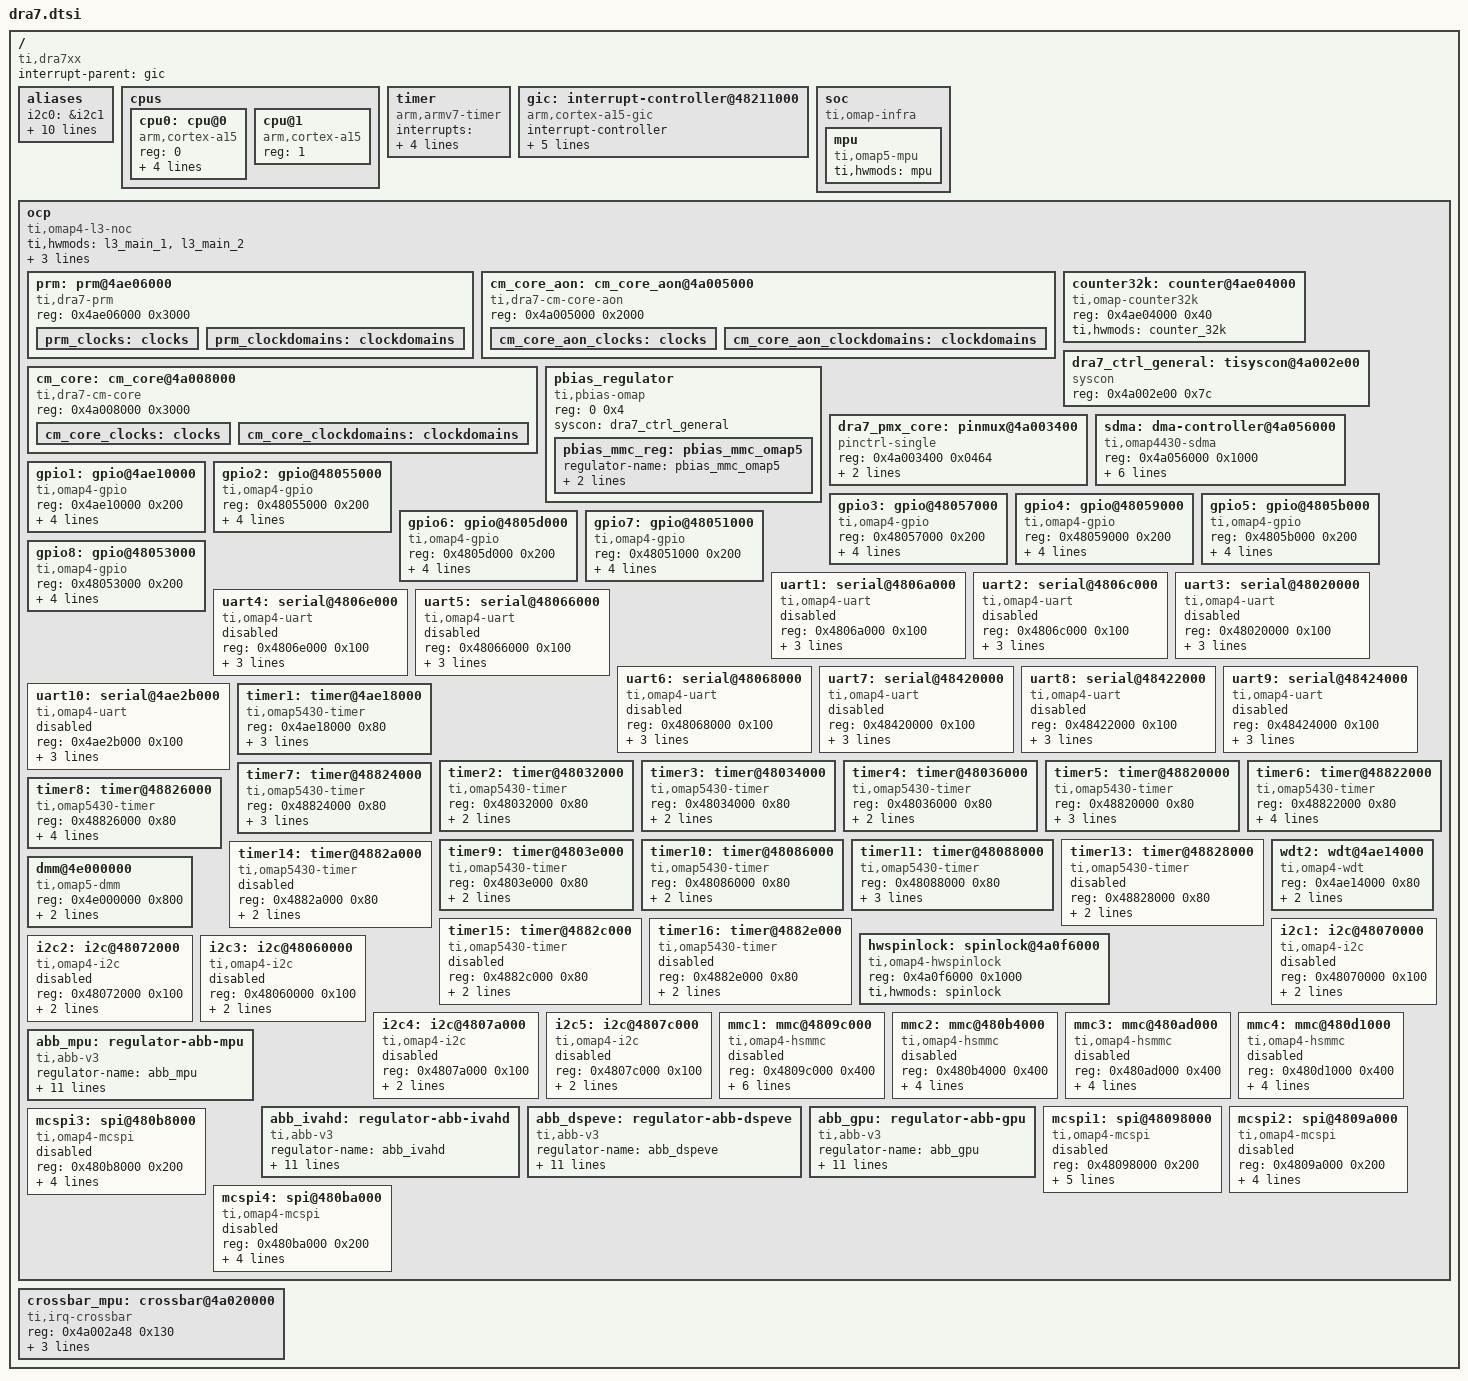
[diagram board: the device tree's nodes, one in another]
/*
 * Copyright (C) 2013 Texas Instruments Incorporated - http://www.ti.com/
 *
 * This program is free software; you can redistribute it and/or modify
 * it under the terms of the GNU General Public License version 2 as
 * published by the Free Software Foundation.
 * Based on "omap4.dtsi"
 */

#include <dt-bindings/interrupt-controller/arm-gic.h>
#include <dt-bindings/pinctrl/dra.h>

#include "skeleton.dtsi"

/ {
	#address-cells = <1>;
	#size-cells = <1>;

	compatible = "ti,dra7xx";
	interrupt-parent = <&gic>;

	aliases {
		i2c0 = &i2c1;
		i2c1 = &i2c2;
		i2c2 = &i2c3;
		i2c3 = &i2c4;
		i2c4 = &i2c5;
		serial0 = &uart1;
		serial1 = &uart2;
		serial2 = &uart3;
		serial3 = &uart4;
		serial4 = &uart5;
		serial5 = &uart6;
	};

	cpus {
		#address-cells = <1>;
		#size-cells = <0>;

		cpu0: cpu@0 {
			device_type = "cpu";
			compatible = "arm,cortex-a15";
			reg = <0>;

			operating-points = <
				/* kHz    uV */
				1000000	1060000
				1176000	1160000
				>;

			clocks = <&dpll_mpu_ck>;
			clock-names = "cpu";

			clock-latency = <300000>; /* From omap-cpufreq driver */
		};
		cpu@1 {
			device_type = "cpu";
			compatible = "arm,cortex-a15";
			reg = <1>;
		};
	};

	timer {
		compatible = "arm,armv7-timer";
		interrupts = <GIC_PPI 13 (GIC_CPU_MASK_SIMPLE(2) | IRQ_TYPE_LEVEL_LOW)>,
			     <GIC_PPI 14 (GIC_CPU_MASK_SIMPLE(2) | IRQ_TYPE_LEVEL_LOW)>,
			     <GIC_PPI 11 (GIC_CPU_MASK_SIMPLE(2) | IRQ_TYPE_LEVEL_LOW)>,
			     <GIC_PPI 10 (GIC_CPU_MASK_SIMPLE(2) | IRQ_TYPE_LEVEL_LOW)>;
	};

	gic: interrupt-controller@48211000 {
		compatible = "arm,cortex-a15-gic";
		interrupt-controller;
		#interrupt-cells = <3>;
		arm,routable-irqs = <192>;
		reg = <0x48211000 0x1000>,
		      <0x48212000 0x1000>,
		      <0x48214000 0x2000>,
		      <0x48216000 0x2000>;
		interrupts = <GIC_PPI 9 (GIC_CPU_MASK_SIMPLE(2) | IRQ_TYPE_LEVEL_HIGH)>;
	};

	/*
	 * The soc node represents the soc top level view. It is used for IPs
	 * that are not memory mapped in the MPU view or for the MPU itself.
	 */
	soc {
		compatible = "ti,omap-infra";
		mpu {
			compatible = "ti,omap5-mpu";
			ti,hwmods = "mpu";
		};
	};

	/*
	 * XXX: Use a flat representation of the SOC interconnect.
	 * The real OMAP interconnect network is quite complex.
	 * Since it will not bring real advantage to represent that in DT for
	 * the moment, just use a fake OCP bus entry to represent the whole bus
	 * hierarchy.
	 */
	ocp {
		compatible = "ti,omap4-l3-noc", "simple-bus";
		#address-cells = <1>;
		#size-cells = <1>;
		ranges;
		ti,hwmods = "l3_main_1", "l3_main_2";
		reg = <0x44000000 0x2000>,
		      <0x44800000 0x3000>;
		interrupts = <GIC_SPI 164 IRQ_TYPE_LEVEL_HIGH>,
			     <GIC_SPI 10 IRQ_TYPE_LEVEL_HIGH>;

		prm: prm@4ae06000 {
			compatible = "ti,dra7-prm";
			reg = <0x4ae06000 0x3000>;

			prm_clocks: clocks {
				#address-cells = <1>;
				#size-cells = <0>;
			};

			prm_clockdomains: clockdomains {
			};
		};

		cm_core_aon: cm_core_aon@4a005000 {
			compatible = "ti,dra7-cm-core-aon";
			reg = <0x4a005000 0x2000>;

			cm_core_aon_clocks: clocks {
				#address-cells = <1>;
				#size-cells = <0>;
			};

			cm_core_aon_clockdomains: clockdomains {
			};
		};

		cm_core: cm_core@4a008000 {
			compatible = "ti,dra7-cm-core";
			reg = <0x4a008000 0x3000>;

			cm_core_clocks: clocks {
				#address-cells = <1>;
				#size-cells = <0>;
			};

			cm_core_clockdomains: clockdomains {
			};
		};

		counter32k: counter@4ae04000 {
			compatible = "ti,omap-counter32k";
			reg = <0x4ae04000 0x40>;
			ti,hwmods = "counter_32k";
		};

		dra7_ctrl_general: tisyscon@4a002e00 {
			compatible = "syscon";
			reg = <0x4a002e00 0x7c>;
		};

		pbias_regulator: pbias_regulator {
			compatible = "ti,pbias-omap";
			reg = <0 0x4>;
			syscon = <&dra7_ctrl_general>;
			pbias_mmc_reg: pbias_mmc_omap5 {
				regulator-name = "pbias_mmc_omap5";
				regulator-min-microvolt = <1800000>;
				regulator-max-microvolt = <3000000>;
			};
		};

		dra7_pmx_core: pinmux@4a003400 {
			compatible = "pinctrl-single";
			reg = <0x4a003400 0x0464>;
			#address-cells = <1>;
			#size-cells = <0>;
			pinctrl-single,register-width = <32>;
			pinctrl-single,function-mask = <0x3fffffff>;
		};

		sdma: dma-controller@4a056000 {
			compatible = "ti,omap4430-sdma";
			reg = <0x4a056000 0x1000>;
			interrupts = <GIC_SPI 167 IRQ_TYPE_LEVEL_HIGH>,
				     <GIC_SPI 168 IRQ_TYPE_LEVEL_HIGH>,
				     <GIC_SPI 169 IRQ_TYPE_LEVEL_HIGH>,
				     <GIC_SPI 170 IRQ_TYPE_LEVEL_HIGH>;
			#dma-cells = <1>;
			#dma-channels = <32>;
			#dma-requests = <127>;
		};

		gpio1: gpio@4ae10000 {
			compatible = "ti,omap4-gpio";
			reg = <0x4ae10000 0x200>;
			interrupts = <GIC_SPI 184 IRQ_TYPE_LEVEL_HIGH>;
			ti,hwmods = "gpio1";
			gpio-controller;
			#gpio-cells = <2>;
			interrupt-controller;
			#interrupt-cells = <1>;
		};

		gpio2: gpio@48055000 {
			compatible = "ti,omap4-gpio";
			reg = <0x48055000 0x200>;
			interrupts = <GIC_SPI 185 IRQ_TYPE_LEVEL_HIGH>;
			ti,hwmods = "gpio2";
			gpio-controller;
			#gpio-cells = <2>;
			interrupt-controller;
			#interrupt-cells = <1>;
		};

		gpio3: gpio@48057000 {
			compatible = "ti,omap4-gpio";
			reg = <0x48057000 0x200>;
			interrupts = <GIC_SPI 186 IRQ_TYPE_LEVEL_HIGH>;
			ti,hwmods = "gpio3";
			gpio-controller;
			#gpio-cells = <2>;
			interrupt-controller;
			#interrupt-cells = <1>;
		};

		gpio4: gpio@48059000 {
			compatible = "ti,omap4-gpio";
			reg = <0x48059000 0x200>;
			interrupts = <GIC_SPI 187 IRQ_TYPE_LEVEL_HIGH>;
			ti,hwmods = "gpio4";
			gpio-controller;
			#gpio-cells = <2>;
			interrupt-controller;
			#interrupt-cells = <1>;
		};

		gpio5: gpio@4805b000 {
			compatible = "ti,omap4-gpio";
			reg = <0x4805b000 0x200>;
			interrupts = <GIC_SPI 188 IRQ_TYPE_LEVEL_HIGH>;
			ti,hwmods = "gpio5";
			gpio-controller;
			#gpio-cells = <2>;
			interrupt-controller;
			#interrupt-cells = <1>;
		};

		gpio6: gpio@4805d000 {
			compatible = "ti,omap4-gpio";
			reg = <0x4805d000 0x200>;
			interrupts = <GIC_SPI 189 IRQ_TYPE_LEVEL_HIGH>;
			ti,hwmods = "gpio6";
			gpio-controller;
			#gpio-cells = <2>;
			interrupt-controller;
			#interrupt-cells = <1>;
		};

		gpio7: gpio@48051000 {
			compatible = "ti,omap4-gpio";
			reg = <0x48051000 0x200>;
			interrupts = <GIC_SPI 190 IRQ_TYPE_LEVEL_HIGH>;
			ti,hwmods = "gpio7";
			gpio-controller;
			#gpio-cells = <2>;
			interrupt-controller;
			#interrupt-cells = <1>;
		};

		gpio8: gpio@48053000 {
			compatible = "ti,omap4-gpio";
			reg = <0x48053000 0x200>;
			interrupts = <GIC_SPI 276 IRQ_TYPE_LEVEL_HIGH>;
			ti,hwmods = "gpio8";
			gpio-controller;
			#gpio-cells = <2>;
			interrupt-controller;
			#interrupt-cells = <1>;
		};

		uart1: serial@4806a000 {
			compatible = "ti,omap4-uart";
			reg = <0x4806a000 0x100>;
			interrupts = <GIC_SPI 227 IRQ_TYPE_LEVEL_HIGH>;
			ti,hwmods = "uart1";
			clock-frequency = <48000000>;
			status = "disabled";
		};

		uart2: serial@4806c000 {
			compatible = "ti,omap4-uart";
			reg = <0x4806c000 0x100>;
			interrupts = <GIC_SPI 228 IRQ_TYPE_LEVEL_HIGH>;
			ti,hwmods = "uart2";
			clock-frequency = <48000000>;
			status = "disabled";
		};

		uart3: serial@48020000 {
			compatible = "ti,omap4-uart";
			reg = <0x48020000 0x100>;
			interrupts = <GIC_SPI 229 IRQ_TYPE_LEVEL_HIGH>;
			ti,hwmods = "uart3";
			clock-frequency = <48000000>;
			status = "disabled";
		};

		uart4: serial@4806e000 {
			compatible = "ti,omap4-uart";
			reg = <0x4806e000 0x100>;
			interrupts = <GIC_SPI 225 IRQ_TYPE_LEVEL_HIGH>;
			ti,hwmods = "uart4";
			clock-frequency = <48000000>;
                        status = "disabled";
		};

		uart5: serial@48066000 {
			compatible = "ti,omap4-uart";
			reg = <0x48066000 0x100>;
			interrupts = <GIC_SPI 260 IRQ_TYPE_LEVEL_HIGH>;
			ti,hwmods = "uart5";
			clock-frequency = <48000000>;
			status = "disabled";
		};

		uart6: serial@48068000 {
			compatible = "ti,omap4-uart";
			reg = <0x48068000 0x100>;
			interrupts = <GIC_SPI 261 IRQ_TYPE_LEVEL_HIGH>;
			ti,hwmods = "uart6";
			clock-frequency = <48000000>;
			status = "disabled";
		};

		uart7: serial@48420000 {
			compatible = "ti,omap4-uart";
			reg = <0x48420000 0x100>;
			interrupts = <GIC_SPI 378 IRQ_TYPE_LEVEL_HIGH>;
			ti,hwmods = "uart7";
			clock-frequency = <48000000>;
			status = "disabled";
		};

		uart8: serial@48422000 {
			compatible = "ti,omap4-uart";
			reg = <0x48422000 0x100>;
			interrupts = <GIC_SPI 379 IRQ_TYPE_LEVEL_HIGH>;
			ti,hwmods = "uart8";
			clock-frequency = <48000000>;
			status = "disabled";
		};

		uart9: serial@48424000 {
			compatible = "ti,omap4-uart";
			reg = <0x48424000 0x100>;
			interrupts = <GIC_SPI 380 IRQ_TYPE_LEVEL_HIGH>;
			ti,hwmods = "uart9";
			clock-frequency = <48000000>;
			status = "disabled";
		};

		uart10: serial@4ae2b000 {
			compatible = "ti,omap4-uart";
			reg = <0x4ae2b000 0x100>;
			interrupts = <GIC_SPI 381 IRQ_TYPE_LEVEL_HIGH>;
			ti,hwmods = "uart10";
			clock-frequency = <48000000>;
			status = "disabled";
		};

		timer1: timer@4ae18000 {
			compatible = "ti,omap5430-timer";
			reg = <0x4ae18000 0x80>;
			interrupts = <GIC_SPI 192 IRQ_TYPE_LEVEL_HIGH>;
			ti,hwmods = "timer1";
			ti,timer-alwon;
		};

		timer2: timer@48032000 {
			compatible = "ti,omap5430-timer";
			reg = <0x48032000 0x80>;
			interrupts = <GIC_SPI 193 IRQ_TYPE_LEVEL_HIGH>;
			ti,hwmods = "timer2";
		};

		timer3: timer@48034000 {
			compatible = "ti,omap5430-timer";
			reg = <0x48034000 0x80>;
			interrupts = <GIC_SPI 194 IRQ_TYPE_LEVEL_HIGH>;
			ti,hwmods = "timer3";
		};

		timer4: timer@48036000 {
			compatible = "ti,omap5430-timer";
			reg = <0x48036000 0x80>;
			interrupts = <GIC_SPI 195 IRQ_TYPE_LEVEL_HIGH>;
			ti,hwmods = "timer4";
		};

		timer5: timer@48820000 {
			compatible = "ti,omap5430-timer";
			reg = <0x48820000 0x80>;
			interrupts = <GIC_SPI 196 IRQ_TYPE_LEVEL_HIGH>;
			ti,hwmods = "timer5";
			ti,timer-dsp;
		};

		timer6: timer@48822000 {
			compatible = "ti,omap5430-timer";
			reg = <0x48822000 0x80>;
			interrupts = <GIC_SPI 197 IRQ_TYPE_LEVEL_HIGH>;
			ti,hwmods = "timer6";
			ti,timer-dsp;
			ti,timer-pwm;
		};

		timer7: timer@48824000 {
			compatible = "ti,omap5430-timer";
			reg = <0x48824000 0x80>;
			interrupts = <GIC_SPI 198 IRQ_TYPE_LEVEL_HIGH>;
			ti,hwmods = "timer7";
			ti,timer-dsp;
		};

		timer8: timer@48826000 {
			compatible = "ti,omap5430-timer";
			reg = <0x48826000 0x80>;
			interrupts = <GIC_SPI 199 IRQ_TYPE_LEVEL_HIGH>;
			ti,hwmods = "timer8";
			ti,timer-dsp;
			ti,timer-pwm;
		};

		timer9: timer@4803e000 {
			compatible = "ti,omap5430-timer";
			reg = <0x4803e000 0x80>;
			interrupts = <GIC_SPI 200 IRQ_TYPE_LEVEL_HIGH>;
			ti,hwmods = "timer9";
		};

		timer10: timer@48086000 {
			compatible = "ti,omap5430-timer";
			reg = <0x48086000 0x80>;
			interrupts = <GIC_SPI 201 IRQ_TYPE_LEVEL_HIGH>;
			ti,hwmods = "timer10";
		};

		timer11: timer@48088000 {
			compatible = "ti,omap5430-timer";
			reg = <0x48088000 0x80>;
			interrupts = <GIC_SPI 202 IRQ_TYPE_LEVEL_HIGH>;
			ti,hwmods = "timer11";
			ti,timer-pwm;
		};

		timer13: timer@48828000 {
			compatible = "ti,omap5430-timer";
			reg = <0x48828000 0x80>;
			interrupts = <GIC_SPI 499 IRQ_TYPE_LEVEL_HIGH>;
			ti,hwmods = "timer13";
			status = "disabled";
		};

		timer14: timer@4882a000 {
			compatible = "ti,omap5430-timer";
			reg = <0x4882a000 0x80>;
			interrupts = <GIC_SPI 500 IRQ_TYPE_LEVEL_HIGH>;
			ti,hwmods = "timer14";
			status = "disabled";
		};

		timer15: timer@4882c000 {
			compatible = "ti,omap5430-timer";
			reg = <0x4882c000 0x80>;
			interrupts = <GIC_SPI 501 IRQ_TYPE_LEVEL_HIGH>;
			ti,hwmods = "timer15";
			status = "disabled";
		};

		timer16: timer@4882e000 {
			compatible = "ti,omap5430-timer";
			reg = <0x4882e000 0x80>;
			interrupts = <GIC_SPI 502 IRQ_TYPE_LEVEL_HIGH>;
			ti,hwmods = "timer16";
			status = "disabled";
		};

		wdt2: wdt@4ae14000 {
			compatible = "ti,omap4-wdt";
			reg = <0x4ae14000 0x80>;
			interrupts = <GIC_SPI 235 IRQ_TYPE_LEVEL_HIGH>;
			ti,hwmods = "wd_timer2";
		};

		hwspinlock: spinlock@4a0f6000 {
			compatible = "ti,omap4-hwspinlock";
			reg = <0x4a0f6000 0x1000>;
			ti,hwmods = "spinlock";
			#hwlock-cells = <1>;
		};

		dmm@4e000000 {
			compatible = "ti,omap5-dmm";
			reg = <0x4e000000 0x800>;
			interrupts = <GIC_SPI 268 IRQ_TYPE_LEVEL_HIGH>;
			ti,hwmods = "dmm";
		};

		i2c1: i2c@48070000 {
			compatible = "ti,omap4-i2c";
			reg = <0x48070000 0x100>;
			interrupts = <GIC_SPI 211 IRQ_TYPE_LEVEL_HIGH>;
			#address-cells = <1>;
			#size-cells = <0>;
			ti,hwmods = "i2c1";
			status = "disabled";
		};

		i2c2: i2c@48072000 {
			compatible = "ti,omap4-i2c";
			reg = <0x48072000 0x100>;
			interrupts = <GIC_SPI 212 IRQ_TYPE_LEVEL_HIGH>;
			#address-cells = <1>;
			#size-cells = <0>;
			ti,hwmods = "i2c2";
			status = "disabled";
		};

		i2c3: i2c@48060000 {
			compatible = "ti,omap4-i2c";
			reg = <0x48060000 0x100>;
			interrupts = <GIC_SPI 216 IRQ_TYPE_LEVEL_HIGH>;
			#address-cells = <1>;
			#size-cells = <0>;
			ti,hwmods = "i2c3";
			status = "disabled";
		};

		i2c4: i2c@4807a000 {
			compatible = "ti,omap4-i2c";
			reg = <0x4807a000 0x100>;
			interrupts = <GIC_SPI 217 IRQ_TYPE_LEVEL_HIGH>;
			#address-cells = <1>;
			#size-cells = <0>;
			ti,hwmods = "i2c4";
			status = "disabled";
		};

		i2c5: i2c@4807c000 {
			compatible = "ti,omap4-i2c";
			reg = <0x4807c000 0x100>;
			interrupts = <GIC_SPI 215 IRQ_TYPE_LEVEL_HIGH>;
			#address-cells = <1>;
			#size-cells = <0>;
			ti,hwmods = "i2c5";
			status = "disabled";
		};

		mmc1: mmc@4809c000 {
			compatible = "ti,omap4-hsmmc";
			reg = <0x4809c000 0x400>;
			interrupts = <GIC_SPI 238 IRQ_TYPE_LEVEL_HIGH>;
			ti,hwmods = "mmc1";
			ti,dual-volt;
			ti,needs-special-reset;
			dmas = <&sdma 61>, <&sdma 62>;
			dma-names = "tx", "rx";
			status = "disabled";
			pbias-supply = <&pbias_mmc_reg>;
		};

		mmc2: mmc@480b4000 {
			compatible = "ti,omap4-hsmmc";
			reg = <0x480b4000 0x400>;
			interrupts = <GIC_SPI 241 IRQ_TYPE_LEVEL_HIGH>;
			ti,hwmods = "mmc2";
			ti,needs-special-reset;
			dmas = <&sdma 47>, <&sdma 48>;
			dma-names = "tx", "rx";
			status = "disabled";
		};

		mmc3: mmc@480ad000 {
			compatible = "ti,omap4-hsmmc";
			reg = <0x480ad000 0x400>;
			interrupts = <GIC_SPI 249 IRQ_TYPE_LEVEL_HIGH>;
			ti,hwmods = "mmc3";
			ti,needs-special-reset;
			dmas = <&sdma 77>, <&sdma 78>;
			dma-names = "tx", "rx";
			status = "disabled";
		};

		mmc4: mmc@480d1000 {
			compatible = "ti,omap4-hsmmc";
			reg = <0x480d1000 0x400>;
			interrupts = <GIC_SPI 251 IRQ_TYPE_LEVEL_HIGH>;
			ti,hwmods = "mmc4";
			ti,needs-special-reset;
			dmas = <&sdma 57>, <&sdma 58>;
			dma-names = "tx", "rx";
			status = "disabled";
		};

		abb_mpu: regulator-abb-mpu {
			compatible = "ti,abb-v3";
			regulator-name = "abb_mpu";
			#address-cells = <0>;
			#size-cells = <0>;
			clocks = <&sys_clkin1>;
			ti,settling-time = <50>;
			ti,clock-cycles = <16>;

			reg = <0x4ae07ddc 0x4>, <0x4ae07de0 0x4>,
			      <0x4ae06014 0x4>, <0x4a003b20 0x8>,
			      <0x4ae0c158 0x4>;
			reg-names = "setup-address", "control-address",
				    "int-address", "efuse-address",
				    "ldo-address";
			ti,tranxdone-status-mask = <0x80>;
			/* LDOVBBMPU_FBB_MUX_CTRL */
			ti,ldovbb-override-mask = <0x400>;
			/* LDOVBBMPU_FBB_VSET_OUT */
			ti,ldovbb-vset-mask = <0x1F>;

			/*
			 * NOTE: only FBB mode used but actual vset will
			 * determine final biasing
			 */
			ti,abb_info = <
			/*uV		ABB	efuse	rbb_m fbb_m	vset_m*/
			1060000		0	0x0	0 0x02000000 0x01F00000
			1160000		0	0x4	0 0x02000000 0x01F00000
			1210000		0	0x8	0 0x02000000 0x01F00000
			>;
		};

		abb_ivahd: regulator-abb-ivahd {
			compatible = "ti,abb-v3";
			regulator-name = "abb_ivahd";
			#address-cells = <0>;
			#size-cells = <0>;
			clocks = <&sys_clkin1>;
			ti,settling-time = <50>;
			ti,clock-cycles = <16>;

			reg = <0x4ae07e34 0x4>, <0x4ae07e24 0x4>,
			      <0x4ae06010 0x4>, <0x4a0025cc 0x8>,
			      <0x4a002470 0x4>;
			reg-names = "setup-address", "control-address",
				    "int-address", "efuse-address",
				    "ldo-address";
			ti,tranxdone-status-mask = <0x40000000>;
			/* LDOVBBIVA_FBB_MUX_CTRL */
			ti,ldovbb-override-mask = <0x400>;
			/* LDOVBBIVA_FBB_VSET_OUT */
			ti,ldovbb-vset-mask = <0x1F>;

			/*
			 * NOTE: only FBB mode used but actual vset will
			 * determine final biasing
			 */
			ti,abb_info = <
			/*uV		ABB	efuse	rbb_m fbb_m	vset_m*/
			1055000		0	0x0	0 0x02000000 0x01F00000
			1150000		0	0x4	0 0x02000000 0x01F00000
			1250000		0	0x8	0 0x02000000 0x01F00000
			>;
		};

		abb_dspeve: regulator-abb-dspeve {
			compatible = "ti,abb-v3";
			regulator-name = "abb_dspeve";
			#address-cells = <0>;
			#size-cells = <0>;
			clocks = <&sys_clkin1>;
			ti,settling-time = <50>;
			ti,clock-cycles = <16>;

			reg = <0x4ae07e30 0x4>, <0x4ae07e20 0x4>,
			      <0x4ae06010 0x4>, <0x4a0025e0 0x8>,
			      <0x4a00246c 0x4>;
			reg-names = "setup-address", "control-address",
				    "int-address", "efuse-address",
				    "ldo-address";
			ti,tranxdone-status-mask = <0x20000000>;
			/* LDOVBBDSPEVE_FBB_MUX_CTRL */
			ti,ldovbb-override-mask = <0x400>;
			/* LDOVBBDSPEVE_FBB_VSET_OUT */
			ti,ldovbb-vset-mask = <0x1F>;

			/*
			 * NOTE: only FBB mode used but actual vset will
			 * determine final biasing
			 */
			ti,abb_info = <
			/*uV		ABB	efuse	rbb_m fbb_m	vset_m*/
			1055000		0	0x0	0 0x02000000 0x01F00000
			1150000		0	0x4	0 0x02000000 0x01F00000
			1250000		0	0x8	0 0x02000000 0x01F00000
			>;
		};

		abb_gpu: regulator-abb-gpu {
			compatible = "ti,abb-v3";
			regulator-name = "abb_gpu";
			#address-cells = <0>;
			#size-cells = <0>;
			clocks = <&sys_clkin1>;
			ti,settling-time = <50>;
			ti,clock-cycles = <16>;

			reg = <0x4ae07de4 0x4>, <0x4ae07de8 0x4>,
			      <0x4ae06010 0x4>, <0x4a003b08 0x8>,
			      <0x4ae0c154 0x4>;
			reg-names = "setup-address", "control-address",
				    "int-address", "efuse-address",
				    "ldo-address";
			ti,tranxdone-status-mask = <0x10000000>;
			/* LDOVBBGPU_FBB_MUX_CTRL */
			ti,ldovbb-override-mask = <0x400>;
			/* LDOVBBGPU_FBB_VSET_OUT */
			ti,ldovbb-vset-mask = <0x1F>;

			/*
			 * NOTE: only FBB mode used but actual vset will
			 * determine final biasing
			 */
			ti,abb_info = <
			/*uV		ABB	efuse	rbb_m fbb_m	vset_m*/
			1090000		0	0x0	0 0x02000000 0x01F00000
			1210000		0	0x4	0 0x02000000 0x01F00000
			1280000		0	0x8	0 0x02000000 0x01F00000
			>;
		};

		mcspi1: spi@48098000 {
			compatible = "ti,omap4-mcspi";
			reg = <0x48098000 0x200>;
			interrupts = <GIC_SPI 220 IRQ_TYPE_LEVEL_HIGH>;
			#address-cells = <1>;
			#size-cells = <0>;
			ti,hwmods = "mcspi1";
			ti,spi-num-cs = <4>;
			dmas = <&sdma 35>,
			       <&sdma 36>,
			       <&sdma 37>,
			       <&sdma 38>,
			       <&sdma 39>,
			       <&sdma 40>,
			       <&sdma 41>,
			       <&sdma 42>;
			dma-names = "tx0", "rx0", "tx1", "rx1",
				    "tx2", "rx2", "tx3", "rx3";
			status = "disabled";
		};

		mcspi2: spi@4809a000 {
			compatible = "ti,omap4-mcspi";
			reg = <0x4809a000 0x200>;
			interrupts = <GIC_SPI 221 IRQ_TYPE_LEVEL_HIGH>;
			#address-cells = <1>;
			#size-cells = <0>;
			ti,hwmods = "mcspi2";
			ti,spi-num-cs = <2>;
			dmas = <&sdma 43>,
			       <&sdma 44>,
			       <&sdma 45>,
			       <&sdma 46>;
			dma-names = "tx0", "rx0", "tx1", "rx1";
			status = "disabled";
		};

		mcspi3: spi@480b8000 {
			compatible = "ti,omap4-mcspi";
			reg = <0x480b8000 0x200>;
			interrupts = <GIC_SPI 246 IRQ_TYPE_LEVEL_HIGH>;
			#address-cells = <1>;
			#size-cells = <0>;
			ti,hwmods = "mcspi3";
			ti,spi-num-cs = <2>;
			dmas = <&sdma 15>, <&sdma 16>;
			dma-names = "tx0", "rx0";
			status = "disabled";
		};

		mcspi4: spi@480ba000 {
			compatible = "ti,omap4-mcspi";
			reg = <0x480ba000 0x200>;
			interrupts = <GIC_SPI 203 IRQ_TYPE_LEVEL_HIGH>;
			#address-cells = <1>;
			#size-cells = <0>;
			ti,hwmods = "mcspi4";
			ti,spi-num-cs = <1>;
			dmas = <&sdma 70>, <&sdma 71>;
			dma-names = "tx0", "rx0";
			status = "disabled";
		};
	};

	crossbar_mpu: crossbar@4a020000 {
		compatible = "ti,irq-crossbar";
		reg = <0x4a002a48 0x130>;
		ti,max-irqs = <160>;
		ti,reg-size = <2>;
		ti,irqs-reserved = <0 1 2 3 5 6 131 132>;
	};
};

/include/ "dra7xx-clocks.dtsi"
